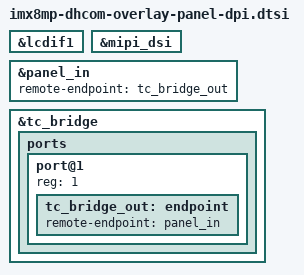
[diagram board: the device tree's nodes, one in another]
// SPDX-License-Identifier: (GPL-2.0+ OR MIT)
/*
 * Copyright (C) 2022-2026 Marek Vasut
 */

#include "imx8mp-dhcom-overlay-panel-common.dtsi"

&lcdif1 {
	status = "okay";
};

&mipi_dsi {
	status = "okay";
};

&panel_in {
	remote-endpoint = <&tc_bridge_out>;
};

&tc_bridge {
	status = "okay";

	ports {
		#address-cells = <1>;
		#size-cells = <0>;

		port@1 {
			reg = <1>;

			tc_bridge_out: endpoint {
				remote-endpoint = <&panel_in>;
			};
		};
	};
};
